# APM32F030 register map
File version: 1.0
Registers are 32-bit, read-write, reset 0x0 unless marked. A register's access mark holds for its fields unless they carry their own. Offsets are from the block's base; [hi:lo] are bit positions.

## TMR6 — Basic-timers
Base 0x40001000
Same registers: TMR7 0x40001400
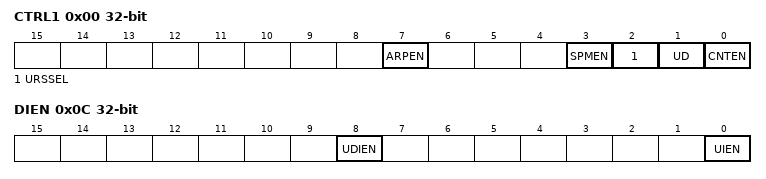
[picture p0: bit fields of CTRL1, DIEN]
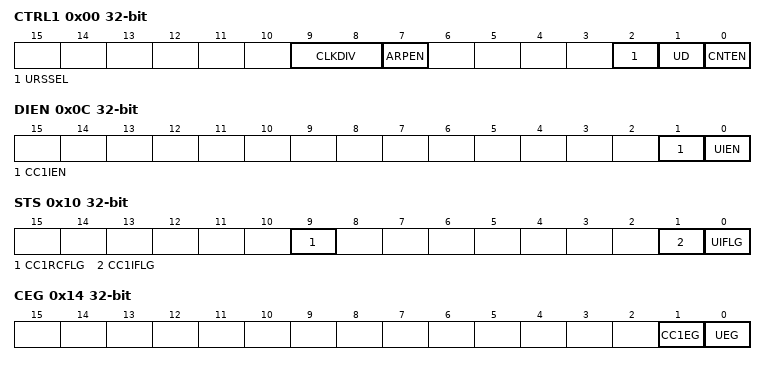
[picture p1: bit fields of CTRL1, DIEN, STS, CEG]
0x00 CTRL1 — control register 1
  [7] ARPEN — Auto-reload preload enable
  [3] SPMEN — One-pulse mode
  [2] URSSEL — Update request source
  [1] UD — Update disable
  [0] CNTEN — Counter enable
0x0C DIEN — DMA/Interrupt enable register
  [8] UDIEN — Update DMA request enable
  [0] UIEN — Update interrupt enable
0x10 STS — status register
  [0] UIFLG — Update interrupt flag
0x14 CEG wo — event generation register
  [0] UEG — Update generation
0x24 CNT — counter
  [15:0] CNT — Low counter value
0x28 PSC — prescaler
  [15:0] PSC — Prescaler value
0x2C AUTORLD reset 0xFFFF — auto-reload register
  [15:0] AUTORLD — Low Auto-reload value

## TMR14 — General-purpose-timers
Base 0x40002000
0x00 CTRL1 — control register 1
  [9:8] CLKDIV — Clock division
  [7] ARPEN — Auto-reload preload enable
  [2] URSSEL — Update request source
  [1] UD — Update disable
  [0] CNTEN — Counter enable
0x0C DIEN — DMA/Interrupt enable register
  [1] CC1IEN — Capture/Compare 1 interrupt enable
  [0] UIEN — Update interrupt enable
0x10 STS — status register
  [9] CC1RCFLG — Capture/Compare 1 overcapture flag
  [1] CC1IFLG — Capture/compare 1 interrupt flag
  [0] UIFLG — Update interrupt flag
0x14 CEG wo — event generation register
  [1] CC1EG — Capture/compare 1 generation
  [0] UEG — Update generation
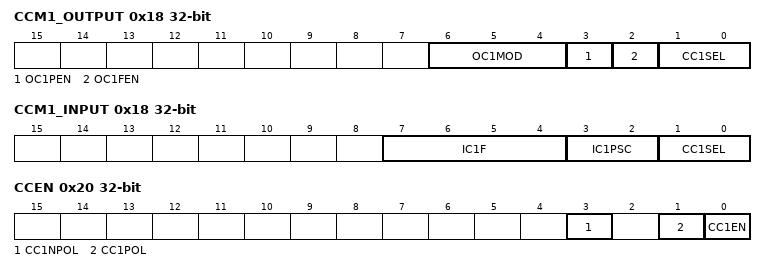
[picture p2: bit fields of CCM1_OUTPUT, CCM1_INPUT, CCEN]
0x18 CCM1_OUTPUT — capture/compare mode register (output mode)
  [6:4] OC1MOD — Output Compare 1 mode
  [3] OC1PEN — Output Compare 1 preload enable
  [2] OC1FEN — Output Compare 1 fast enable
  [1:0] CC1SEL — Capture/Compare 1 selection
0x18 CCM1_INPUT (alternate view of CCM1_OUTPUT) — capture/compare mode register 1 (input mode)
  [7:4] IC1F — Input capture 1 filter
  [3:2] IC1PSC — Input capture 1 prescaler
  [1:0] CC1SEL — Capture/Compare 1 selection
0x20 CCEN — capture/compare enable register
  [3] CC1NPOL — Capture/Compare 1 output Polarity
  [1] CC1POL — Capture/Compare 1 output Polarity
  [0] CC1EN — Capture/Compare 1 output enable
0x24 CNT — counter
  [15:0] CNT — counter value
0x28 PSC — prescaler
  [15:0] PSC — Prescaler value
0x2C AUTORLD reset 0xFFFF — auto-reload register
  [15:0] AUTORLD — Auto-reload value
0x34 CC1 — capture/compare register 1
  [15:0] CC1 — Capture/Compare 1 value
0x50 OPT — option register
  [1:0] RMPSEL — Timer input 1 remap

## TMR15 — General-purpose-timers
Base 0x40014000
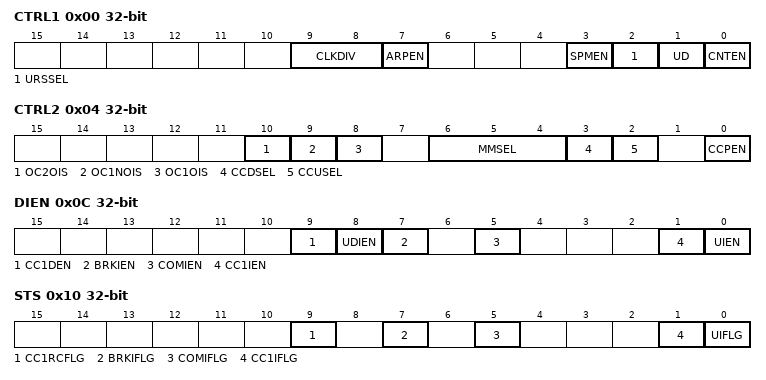
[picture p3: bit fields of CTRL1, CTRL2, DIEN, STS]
0x00 CTRL1 — control register 1
  [9:8] CLKDIV — Clock division
  [7] ARPEN — Auto-reload preload enable
  [3] SPMEN — One-pulse mode
  [2] URSSEL — Update request source
  [1] UD — Update disable
  [0] CNTEN — Counter enable
0x04 CTRL2 — control register 2
  [10] OC2OIS — Output Idle state 2
  [9] OC1NOIS — Output Idle state 1
  [8] OC1OIS — Output Idle state 1
  [6:4] MMSEL — Master Mode Signal Select
  [3] CCDSEL — Capture/compare DMA selection
  [2] CCUSEL — Capture/compare control update selection
  [0] CCPEN — Capture/compare preloaded control
0x0C DIEN — DMA/Interrupt enable register
  [9] CC1DEN — Capture/Compare 1 DMA request enable
  [8] UDIEN — Update DMA request enable
  [7] BRKIEN — Break interrupt enable
  [5] COMIEN — COM interrupt enable
  [1] CC1IEN — Capture/Compare 1 interrupt enable
  [0] UIEN — Update interrupt enable
0x10 STS — status register
  [9] CC1RCFLG — Capture/Compare 1 overcapture flag
  [7] BRKIFLG — Break interrupt flag
  [5] COMIFLG — COM interrupt flag
  [1] CC1IFLG — Capture/compare 1 interrupt flag
  [0] UIFLG — Update interrupt flag
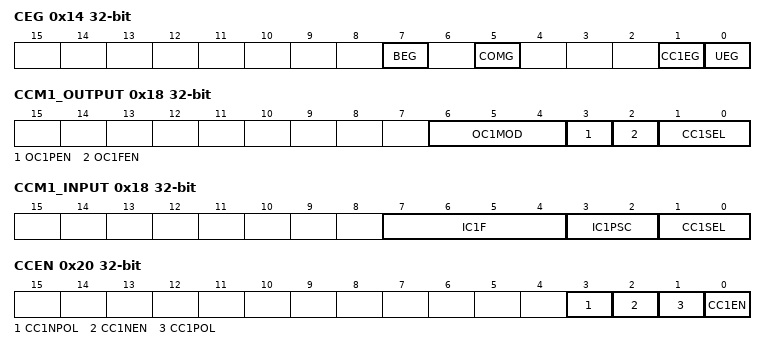
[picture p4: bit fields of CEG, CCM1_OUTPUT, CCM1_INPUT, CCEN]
0x14 CEG wo — event generation register
  [7] BEG — Break generation
  [5] COMG — Capture/Compare control update generation
  [1] CC1EG — Capture/compare 1 generation
  [0] UEG — Update generation
0x18 CCM1_OUTPUT — capture/compare mode register (output mode)
  [6:4] OC1MOD — Output Compare 1 mode
  [3] OC1PEN — Output Compare 1 preload enable
  [2] OC1FEN — Output Compare 1 fast enable
  [1:0] CC1SEL — Capture/Compare 1 selection
0x18 CCM1_INPUT (alternate view of CCM1_OUTPUT) — capture/compare mode register 1 (input mode)
  [7:4] IC1F — Input capture 1 filter
  [3:2] IC1PSC — Input capture 1 prescaler
  [1:0] CC1SEL — Capture/Compare 1 selection
0x20 CCEN — capture/compare enable register
  [3] CC1NPOL — Capture/Compare 1 output Polarity
  [2] CC1NEN — Capture/Compare 1 complementary output enable
  [1] CC1POL — Capture/Compare 1 output Polarity
  [0] CC1EN — Capture/Compare 1 output enable
0x24 CNT — counter
  [15:0] CNT — counter value
0x28 PSC — prescaler
  [15:0] PSC — Prescaler value
0x2C AUTORLD reset 0xFFFF — auto-reload register
  [15:0] AUTORLD — Auto-reload value
0x30 REPCNT — repetition counter register
  [7:0] REPCNT — Repetition counter value
0x34 CC1 — capture/compare register 1
  [15:0] CC1 — Capture/Compare 1 value
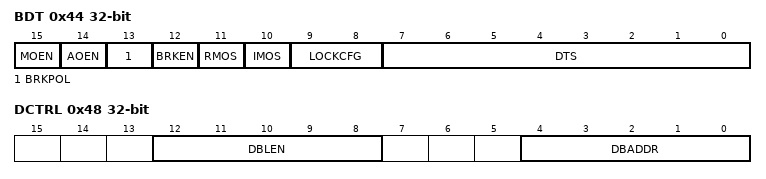
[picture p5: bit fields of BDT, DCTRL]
0x44 BDT — break and dead-time register
  [15] MOEN — Main output enable
  [14] AOEN — Automatic output enable
  [13] BRKPOL — Break polarity
  [12] BRKEN — Break enable
  [11] RMOS — Off-state selection for Run mode
  [10] IMOS — Off-state selection for Idle mode
  [9:8] LOCKCFG — Lock configuration
  [7:0] DTS — Dead-time generator setup
0x48 DCTRL — DMA control register
  [12:8] DBLEN — DMA burst length
  [4:0] DBADDR — DMA base address
0x4C DMADDR — DMA address for full transfer
  [15:0] DMADDR — DMA register for burst accesses

## TMR16 — General-purpose-timers
Base 0x40014400
Same registers: TMR17 0x40014800
Registers as TMR15; these are added or differ:
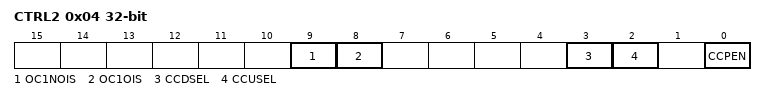
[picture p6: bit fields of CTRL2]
0x04 CTRL2 — control register 2
  [9] OC1NOIS — Output Idle state 1
  [8] OC1OIS — Output Idle state 1
  [3] CCDSEL — Capture/compare DMA selection
  [2] CCUSEL — Capture/compare control update selection
  [0] CCPEN — Capture/compare preloaded control
